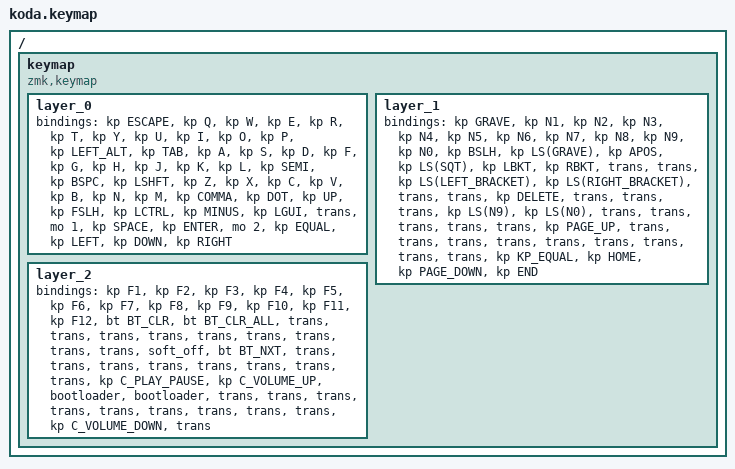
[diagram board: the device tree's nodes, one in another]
#include <behaviors.dtsi>
#include <dt-bindings/zmk/bt.h>
#include <dt-bindings/zmk/keys.h>

/ {
    keymap {
        compatible = "zmk,keymap";

        layer_0 {
            bindings = <
&kp ESCAPE  &kp Q  &kp W  &kp E  &kp R  &kp T  &kp Y  &kp U  &kp I  &kp O  &kp P  &kp LEFT_ALT  &kp TAB  &kp A  &kp S  &kp D  &kp F  &kp G  &kp H  &kp J  &kp K  &kp L  &kp SEMI  &kp BSPC  &kp LSHFT  &kp Z  &kp X  &kp C  &kp V  &kp B  &kp N  &kp M  &kp COMMA  &kp DOT  &kp UP  &kp FSLH  &kp LCTRL  &kp MINUS  &kp LGUI  &trans  &mo 1  &kp SPACE  &kp ENTER  &mo 2  &kp EQUAL  &kp LEFT  &kp DOWN  &kp RIGHT
            >;
        };

        layer_1 {
            bindings = <
&kp GRAVE  &kp N1  &kp N2  &kp N3  &kp N4  &kp N5  &kp N6  &kp N7  &kp N8  &kp N9  &kp N0  &kp BSLH  &kp LS(GRAVE)  &kp APOS  &kp LS(SQT)  &kp LBKT  &kp RBKT  &trans  &trans  &kp LS(LEFT_BRACKET)  &kp LS(RIGHT_BRACKET)  &trans  &trans  &kp DELETE  &trans  &trans  &trans  &kp LS(N9)  &kp LS(N0)  &trans  &trans  &trans  &trans  &trans  &kp PAGE_UP  &trans  &trans  &trans  &trans  &trans  &trans  &trans  &trans  &trans  &kp KP_EQUAL  &kp HOME  &kp PAGE_DOWN  &kp END
            >;
        };

        layer_2 {
            bindings = <
&kp F1  &kp F2  &kp F3  &kp F4  &kp F5  &kp F6  &kp F7  &kp F8  &kp F9  &kp F10  &kp F11  &kp F12  &bt BT_CLR  &bt BT_CLR_ALL  &trans  &trans  &trans  &trans  &trans  &trans  &trans  &trans  &trans  &soft_off  &bt BT_NXT  &trans  &trans  &trans  &trans  &trans  &trans  &trans  &trans  &kp C_PLAY_PAUSE  &kp C_VOLUME_UP  &bootloader  &bootloader  &trans  &trans  &trans  &trans  &trans  &trans  &trans  &trans  &trans  &kp C_VOLUME_DOWN  &trans
            >;
        };
    };
};
